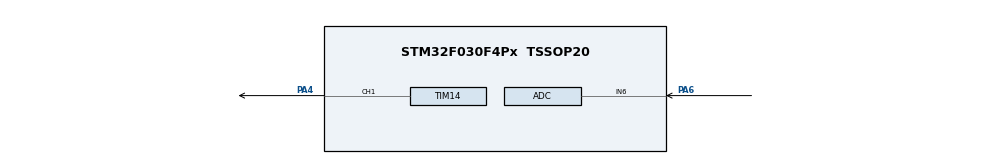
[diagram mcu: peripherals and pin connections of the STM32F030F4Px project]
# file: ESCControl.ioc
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ADC.ContinuousConvMode=ENABLE
ADC.SamplingTime=ADC_SAMPLETIME_71CYCLES_5
Mcu.Family=STM32F0
Mcu.Name=STM32F030F4Px
Mcu.Package=TSSOP20
PA4.Signal=S_TIM14_CH1
PA6.Mode=IN6
PA6.Signal=ADC_IN6
ProjectManager.HeapSize=0x200
ProjectManager.StackSize=0x400
ProjectManager.TargetToolchain=SW4STM32
SH.S_TIM14_CH1.0=TIM14_CH1,PWM Generation1 CH1
TIM14.Channel=TIM_CHANNEL_1
TIM14.Period=999
TIM14.Prescaler=159
VP_TIM14_VS_ClockSourceINT.Mode=Enable_Timer
VP_TIM3_VS_ClockSourceINT.Mode=Internal
board=custom

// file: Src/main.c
/* USER CODE BEGIN Header */
/**
  ******************************************************************************
  * @file           : main.c
  * @brief          : Main program body
  ******************************************************************************
  * @attention
  *
  * <h2><center>&copy; Copyright (c) 2019 STMicroelectronics.
  * All rights reserved.</center></h2>
  *
  * This software component is licensed by ST under BSD 3-Clause license,
  * the "License"; You may not use this file except in compliance with the
  * License. You may obtain a copy of the License at:
  *                        opensource.org/licenses/BSD-3-Clause
  *
  ******************************************************************************
  */
/* USER CODE END Header */

#include "main.h"

ADC_HandleTypeDef hadc;

TIM_HandleTypeDef htim3;
TIM_HandleTypeDef htim14;

/* USER CODE BEGIN PV */
uint32_t reading;
uint32_t duty;
/* USER CODE END PV */

void SystemClock_Config(void);
static void MX_GPIO_Init(void);
static void MX_ADC_Init(void);
static void MX_TIM3_Init(void);
static void MX_TIM14_Init(void);

int main(void)
{

  /* MCU Configuration--------------------------------------------------------*/

  /* Reset of all peripherals, Initializes the Flash interface and the Systick. */
  HAL_Init();

  /* Configure the system clock */
  SystemClock_Config();

  /* Initialize all configured peripherals */
  MX_GPIO_Init();
  MX_ADC_Init();
  MX_TIM3_Init();
  MX_TIM14_Init();
  /* USER CODE BEGIN 2 */
  HAL_ADC_Start(&hadc);
  HAL_TIM_PWM_Start(&htim14, TIM_CHANNEL_1);
  /* USER CODE END 2 */

  /* Infinite loop */
  /* USER CODE BEGIN WHILE */
  while (1)
  {

	  reading = HAL_ADC_GetValue(&hadc);
	  if(reading < 42) reading = 41;
	  duty = (reading / 41)+50;
	  TIM14->CCR1 = duty;

    /* USER CODE END WHILE */

  }
}

void SystemClock_Config(void)
{
  RCC_OscInitTypeDef RCC_OscInitStruct = {0};
  RCC_ClkInitTypeDef RCC_ClkInitStruct = {0};

  /** Initializes the CPU, AHB and APB busses clocks
  */
  RCC_OscInitStruct.OscillatorType = RCC_OSCILLATORTYPE_HSI|RCC_OSCILLATORTYPE_HSI14;
  RCC_OscInitStruct.HSIState = RCC_HSI_ON;
  RCC_OscInitStruct.HSI14State = RCC_HSI14_ON;
  RCC_OscInitStruct.HSICalibrationValue = RCC_HSICALIBRATION_DEFAULT;
  RCC_OscInitStruct.HSI14CalibrationValue = 16;
  RCC_OscInitStruct.PLL.PLLState = RCC_PLL_NONE;
  if (HAL_RCC_OscConfig(&RCC_OscInitStruct) != HAL_OK)
  {
    Error_Handler();
  }
  /** Initializes the CPU, AHB and APB busses clocks
  */
  RCC_ClkInitStruct.ClockType = RCC_CLOCKTYPE_HCLK|RCC_CLOCKTYPE_SYSCLK
                              |RCC_CLOCKTYPE_PCLK1;
  RCC_ClkInitStruct.SYSCLKSource = RCC_SYSCLKSOURCE_HSI;
  RCC_ClkInitStruct.AHBCLKDivider = RCC_SYSCLK_DIV1;
  RCC_ClkInitStruct.APB1CLKDivider = RCC_HCLK_DIV1;

  if (HAL_RCC_ClockConfig(&RCC_ClkInitStruct, FLASH_LATENCY_0) != HAL_OK)
  {
    Error_Handler();
  }
}

static void MX_ADC_Init(void)
{

  ADC_ChannelConfTypeDef sConfig = {0};

  /** Configure the global features of the ADC (Clock, Resolution, Data Alignment and number of conversion)
  */
  hadc.Instance = ADC1;
  hadc.Init.ClockPrescaler = ADC_CLOCK_ASYNC_DIV1;
  hadc.Init.Resolution = ADC_RESOLUTION_12B;
  hadc.Init.DataAlign = ADC_DATAALIGN_RIGHT;
  hadc.Init.ScanConvMode = ADC_SCAN_DIRECTION_FORWARD;
  hadc.Init.EOCSelection = ADC_EOC_SINGLE_CONV;
  hadc.Init.LowPowerAutoWait = DISABLE;
  hadc.Init.LowPowerAutoPowerOff = DISABLE;
  hadc.Init.ContinuousConvMode = ENABLE;
  hadc.Init.DiscontinuousConvMode = DISABLE;
  hadc.Init.ExternalTrigConv = ADC_SOFTWARE_START;
  hadc.Init.ExternalTrigConvEdge = ADC_EXTERNALTRIGCONVEDGE_NONE;
  hadc.Init.DMAContinuousRequests = DISABLE;
  hadc.Init.Overrun = ADC_OVR_DATA_PRESERVED;
  if (HAL_ADC_Init(&hadc) != HAL_OK)
  {
    Error_Handler();
  }
  /** Configure for the selected ADC regular channel to be converted.
  */
  sConfig.Channel = ADC_CHANNEL_6;
  sConfig.Rank = ADC_RANK_CHANNEL_NUMBER;
  sConfig.SamplingTime = ADC_SAMPLETIME_71CYCLES_5;
  if (HAL_ADC_ConfigChannel(&hadc, &sConfig) != HAL_OK)
  {
    Error_Handler();
  }

}

static void MX_TIM3_Init(void)
{

  TIM_ClockConfigTypeDef sClockSourceConfig = {0};
  TIM_MasterConfigTypeDef sMasterConfig = {0};

  htim3.Instance = TIM3;
  htim3.Init.Prescaler = 0;
  htim3.Init.CounterMode = TIM_COUNTERMODE_UP;
  htim3.Init.Period = 0;
  htim3.Init.ClockDivision = TIM_CLOCKDIVISION_DIV1;
  htim3.Init.AutoReloadPreload = TIM_AUTORELOAD_PRELOAD_DISABLE;
  if (HAL_TIM_Base_Init(&htim3) != HAL_OK)
  {
    Error_Handler();
  }
  sClockSourceConfig.ClockSource = TIM_CLOCKSOURCE_INTERNAL;
  if (HAL_TIM_ConfigClockSource(&htim3, &sClockSourceConfig) != HAL_OK)
  {
    Error_Handler();
  }
  sMasterConfig.MasterOutputTrigger = TIM_TRGO_RESET;
  sMasterConfig.MasterSlaveMode = TIM_MASTERSLAVEMODE_DISABLE;
  if (HAL_TIMEx_MasterConfigSynchronization(&htim3, &sMasterConfig) != HAL_OK)
  {
    Error_Handler();
  }

}

static void MX_TIM14_Init(void)
{

  TIM_OC_InitTypeDef sConfigOC = {0};

  htim14.Instance = TIM14;
  htim14.Init.Prescaler = 159;
  htim14.Init.CounterMode = TIM_COUNTERMODE_UP;
  htim14.Init.Period = 999;
  htim14.Init.ClockDivision = TIM_CLOCKDIVISION_DIV1;
  htim14.Init.AutoReloadPreload = TIM_AUTORELOAD_PRELOAD_DISABLE;
  if (HAL_TIM_Base_Init(&htim14) != HAL_OK)
  {
    Error_Handler();
  }
  if (HAL_TIM_PWM_Init(&htim14) != HAL_OK)
  {
    Error_Handler();
  }
  sConfigOC.OCMode = TIM_OCMODE_PWM1;
  sConfigOC.Pulse = 0;
  sConfigOC.OCPolarity = TIM_OCPOLARITY_HIGH;
  sConfigOC.OCFastMode = TIM_OCFAST_DISABLE;
  if (HAL_TIM_PWM_ConfigChannel(&htim14, &sConfigOC, TIM_CHANNEL_1) != HAL_OK)
  {
    Error_Handler();
  }
  HAL_TIM_MspPostInit(&htim14);

}

static void MX_GPIO_Init(void)
{

  /* GPIO Ports Clock Enable */
  __HAL_RCC_GPIOA_CLK_ENABLE();

}

void Error_Handler(void)
{
}

/************************ (C) COPYRIGHT STMicroelectronics *****END OF FILE****/
